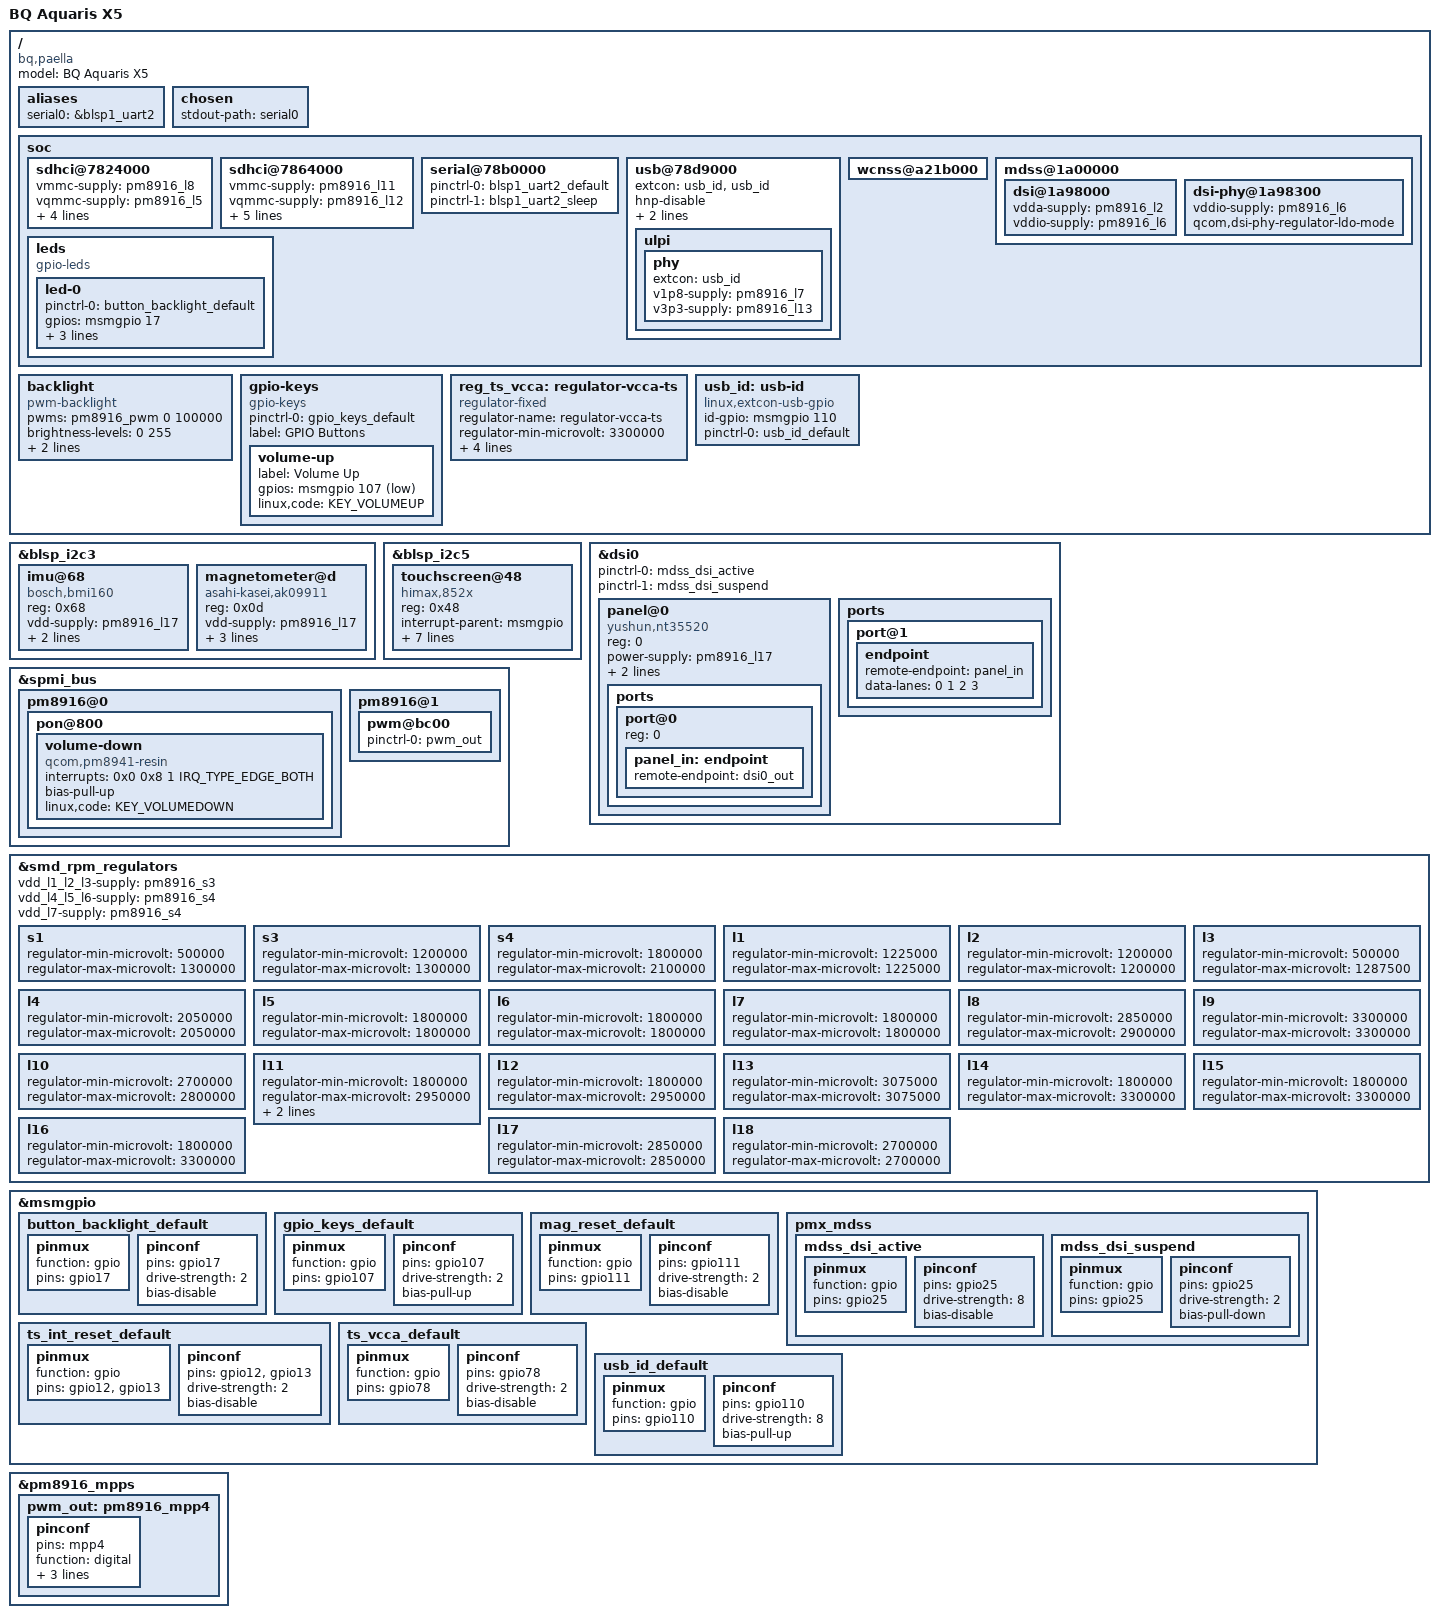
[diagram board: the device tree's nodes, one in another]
// SPDX-License-Identifier: GPL-2.0-only

/dts-v1/;

#include "msm8916.dtsi"
#include "pm8916.dtsi"
#include "arm/qcom-msm8916-no-psci.dtsi"

#include <dt-bindings/gpio/gpio.h>
#include <dt-bindings/input/input.h>
#include <dt-bindings/leds/common.h>
#include <dt-bindings/pinctrl/qcom,pmic-mpp.h>

/ {
	model = "BQ Aquaris X5";
	compatible = "bq,paella", "qcom,msm8916";

	aliases {
		serial0 = &blsp1_uart2;
	};

	chosen {
		stdout-path = "serial0";
	};

	soc {
		sdhci@7824000 {
			status = "okay";

			vmmc-supply = <&pm8916_l8>;
			vqmmc-supply = <&pm8916_l5>;

			pinctrl-names = "default", "sleep";
			pinctrl-0 = <&sdc1_clk_on &sdc1_cmd_on &sdc1_data_on>;
			pinctrl-1 = <&sdc1_clk_off &sdc1_cmd_off &sdc1_data_off>;
		};

		sdhci@7864000 {
			status = "okay";

			vmmc-supply = <&pm8916_l11>;
			vqmmc-supply = <&pm8916_l12>;

			pinctrl-names = "default", "sleep";

			pinctrl-0 = <&sdc2_clk_on &sdc2_cmd_on &sdc2_data_on &sdc2_cd_on>;
			pinctrl-1 = <&sdc2_clk_off &sdc2_cmd_off &sdc2_data_off &sdc2_cd_off>;

			cd-gpios = <&msmgpio 38 GPIO_ACTIVE_LOW>;
		};

		serial@78b0000 {
			status = "okay";
			pinctrl-names = "default", "sleep";
			pinctrl-0 = <&blsp1_uart2_default>;
			pinctrl-1 = <&blsp1_uart2_sleep>;
		};

		usb@78d9000 {
			status = "okay";
			extcon = <&usb_id>, <&usb_id>;

			hnp-disable;
			srp-disable;
			adp-disable;

			ulpi {
				phy {
					extcon = <&usb_id>;
					v1p8-supply = <&pm8916_l7>;
					v3p3-supply = <&pm8916_l13>;
				};
			};
		};

		wcnss@a21b000 {
			status = "okay";
		};

		mdss@1a00000 {
			dsi@1a98000 {
				#address-cells = <1>;
				#size-cells = <0>;

				vdda-supply = <&pm8916_l2>;
				vddio-supply = <&pm8916_l6>;
			};

			dsi-phy@1a98300 {
				vddio-supply = <&pm8916_l6>;
				qcom,dsi-phy-regulator-ldo-mode;
			};
		};

		leds {
			compatible = "gpio-leds";

			led-0 {
				pinctrl-names = "default";
				pinctrl-0 = <&button_backlight_default>;

				gpios = <&msmgpio 17 GPIO_ACTIVE_HIGH>;
				color = <LED_COLOR_ID_WHITE>;
				default-state = "off";
				function = LED_FUNCTION_KBD_BACKLIGHT;
			};
		};
	};

	backlight: backlight {
		compatible = "pwm-backlight";
		pwms = <&pm8916_pwm 0 100000>;

		brightness-levels = <0 255>;
		num-interpolated-steps = <255>;
		default-brightness-level = <255>;
	};

	gpio-keys {
		compatible = "gpio-keys";

		pinctrl-names = "default";
		pinctrl-0 = <&gpio_keys_default>;

		label = "GPIO Buttons";

		volume-up {
			label = "Volume Up";
			gpios = <&msmgpio 107 GPIO_ACTIVE_LOW>;
			linux,code = <KEY_VOLUMEUP>;
		};
	};

	reg_ts_vcca: regulator-vcca-ts {
		compatible = "regulator-fixed";
		regulator-name = "regulator-vcca-ts";
		regulator-min-microvolt = <3300000>;
		regulator-max-microvolt = <3300000>;

		gpio = <&msmgpio 78 GPIO_ACTIVE_HIGH>;
		enable-active-high;

		pinctrl-names = "default";
		pinctrl-0 = <&ts_vcca_default>;
	};

	usb_id: usb-id {
		compatible = "linux,extcon-usb-gpio";
		id-gpio = <&msmgpio 110 GPIO_ACTIVE_HIGH>;
		pinctrl-names = "default";
		pinctrl-0 = <&usb_id_default>;
	};
};

&blsp_i2c3 {
	status = "okay";

	imu@68 {
		compatible = "bosch,bmi160";
		reg = <0x68>;

		vdd-supply = <&pm8916_l17>;
		vddio-supply = <&pm8916_l6>;

		mount-matrix = "0", "1", "0",
			       "-1", "0", "0",
			       "0", "0", "1";
	};

	magnetometer@d {
		compatible = "asahi-kasei,ak09911";
		reg = <0x0d>;

		vdd-supply = <&pm8916_l17>;
		vid-supply = <&pm8916_l6>;

		pinctrl-names = "default";
		pinctrl-0 = <&mag_reset_default>;

		reset-gpios = <&msmgpio 111 GPIO_ACTIVE_LOW>;
	};
};

&blsp_i2c5 {
	status = "okay";

	touchscreen@48 {
		compatible = "himax,852x";
		reg = <0x48>;

		interrupt-parent = <&msmgpio>;
		interrupts = <13 IRQ_TYPE_EDGE_FALLING>;

		reset-gpio = <&msmgpio 12 GPIO_ACTIVE_HIGH>;

		vcca-supply = <&reg_ts_vcca>;
		vccd-supply = <&pm8916_l6>;

		pinctrl-names = "default";
		pinctrl-0 = <&ts_int_reset_default>;

		linux,keycodes = <KEY_BACK KEY_HOMEPAGE KEY_APPSELECT>;
	};
};

&dsi0 {
	pinctrl-names = "default", "sleep";
	pinctrl-0 = <&mdss_dsi_active>;
	pinctrl-1 = <&mdss_dsi_suspend>;

	panel@0 {
		compatible = "yushun,nt35520";
		reg = <0>;

		power-supply = <&pm8916_l17>;
		backlight = <&backlight>;
		reset-gpios = <&msmgpio 25 GPIO_ACTIVE_HIGH>;

		ports {
			#address-cells = <1>;
			#size-cells = <0>;

			port@0 {
				reg = <0>;
				panel_in: endpoint {
					remote-endpoint = <&dsi0_out>;
				};
			};
		};
	};

	ports {
		port@1 {
			endpoint {
				remote-endpoint = <&panel_in>;
				data-lanes = <0 1 2 3>;
			};
		};
	};
};

&spmi_bus {
	pm8916@0 {
		pon@800 {
			volume-down {
				compatible = "qcom,pm8941-resin";
				interrupts = <0x0 0x8 1 IRQ_TYPE_EDGE_BOTH>;
				bias-pull-up;
				linux,code = <KEY_VOLUMEDOWN>;
			};
		};
	};

	pm8916@1 {
		pwm@bc00 {
			status = "okay";
			pinctrl-names = "default";
			pinctrl-0 = <&pwm_out>;
		};
	};
};

&smd_rpm_regulators {
	vdd_l1_l2_l3-supply = <&pm8916_s3>;
	vdd_l4_l5_l6-supply = <&pm8916_s4>;
	vdd_l7-supply = <&pm8916_s4>;

	s1 {
		regulator-min-microvolt = <500000>;
		regulator-max-microvolt = <1300000>;
	};

	s3 {
		regulator-min-microvolt = <1200000>;
		regulator-max-microvolt = <1300000>;
	};

	s4 {
		regulator-min-microvolt = <1800000>;
		regulator-max-microvolt = <2100000>;
	};

	l1 {
		regulator-min-microvolt = <1225000>;
		regulator-max-microvolt = <1225000>;
	};

	l2 {
		regulator-min-microvolt = <1200000>;
		regulator-max-microvolt = <1200000>;
	};

	l3 {
		regulator-min-microvolt = <500000>;
		regulator-max-microvolt = <1287500>;
	};

	l4 {
		regulator-min-microvolt = <2050000>;
		regulator-max-microvolt = <2050000>;
	};

	l5 {
		regulator-min-microvolt = <1800000>;
		regulator-max-microvolt = <1800000>;
	};

	l6 {
		regulator-min-microvolt = <1800000>;
		regulator-max-microvolt = <1800000>;
	};

	l7 {
		regulator-min-microvolt = <1800000>;
		regulator-max-microvolt = <1800000>;
	};

	l8 {
		regulator-min-microvolt = <2850000>;
		regulator-max-microvolt = <2900000>;
	};

	l9 {
		regulator-min-microvolt = <3300000>;
		regulator-max-microvolt = <3300000>;
	};

	l10 {
		regulator-min-microvolt = <2700000>;
		regulator-max-microvolt = <2800000>;
	};

	l11 {
		regulator-min-microvolt = <1800000>;
		regulator-max-microvolt = <2950000>;
		regulator-allow-set-load;
		regulator-system-load = <200000>;
	};

	l12 {
		regulator-min-microvolt = <1800000>;
		regulator-max-microvolt = <2950000>;
	};

	l13 {
		regulator-min-microvolt = <3075000>;
		regulator-max-microvolt = <3075000>;
	};

	l14 {
		regulator-min-microvolt = <1800000>;
		regulator-max-microvolt = <3300000>;
	};

	l15 {
		regulator-min-microvolt = <1800000>;
		regulator-max-microvolt = <3300000>;
	};

	l16 {
		regulator-min-microvolt = <1800000>;
		regulator-max-microvolt = <3300000>;
	};

	l17 {
		regulator-min-microvolt = <2850000>;
		regulator-max-microvolt = <2850000>;
	};

	l18 {
		regulator-min-microvolt = <2700000>;
		regulator-max-microvolt = <2700000>;
	};
};

&msmgpio {
	button_backlight_default: button_backlight_default {
		pinmux {
			function = "gpio";
			pins = "gpio17";
		};
		pinconf {
			pins = "gpio17";
			drive-strength = <2>;
			bias-disable;
		};
	};

	gpio_keys_default: gpio_keys_default {
		pinmux {
			function = "gpio";
			pins = "gpio107";
		};
		pinconf {
			pins = "gpio107";
			drive-strength = <2>;
			bias-pull-up;
		};
	};

	mag_reset_default: mag_reset_default {
		pinmux {
			function = "gpio";
			pins = "gpio111";
		};
		pinconf {
			pins = "gpio111";
			drive-strength = <2>;
			bias-disable;
		};
	};

	pmx_mdss {
		mdss_dsi_active: mdss_dsi_active {
			pinmux {
				function = "gpio";
				pins = "gpio25";
			};
			pinconf {
				pins = "gpio25";
				drive-strength = <8>;
				bias-disable;
			};
		};

		mdss_dsi_suspend: mdss_dsi_suspend {
			pinmux {
				function = "gpio";
				pins = "gpio25";
			};
			pinconf {
				pins = "gpio25";
				drive-strength = <2>;
				bias-pull-down;
			};
		};
	};

	ts_int_reset_default: ts_int_reset_default {
		pinmux {
			function = "gpio";
			pins = "gpio12", "gpio13";
		};
		pinconf {
			pins = "gpio12", "gpio13";
			drive-strength = <2>;
			bias-disable;
		};
	};

	ts_vcca_default: ts_vcca_default {
		pinmux {
			function = "gpio";
			pins = "gpio78";
		};
		pinconf {
			pins = "gpio78";
			drive-strength = <2>;
			bias-disable;
		};
	};

	usb_id_default: usb_id_default {
		pinmux {
			function = "gpio";
			pins = "gpio110";
		};
		pinconf {
			pins = "gpio110";
			drive-strength = <8>;
			bias-pull-up;
		};
	};
};

&pm8916_mpps {
	pwm_out: pm8916_mpp4 {
		pinconf {
			pins = "mpp4";
			function = "digital";
			output-low;
			power-source = <PM8916_MPP_VPH>;
			qcom,dtest = <1>;
		};
	};
};
